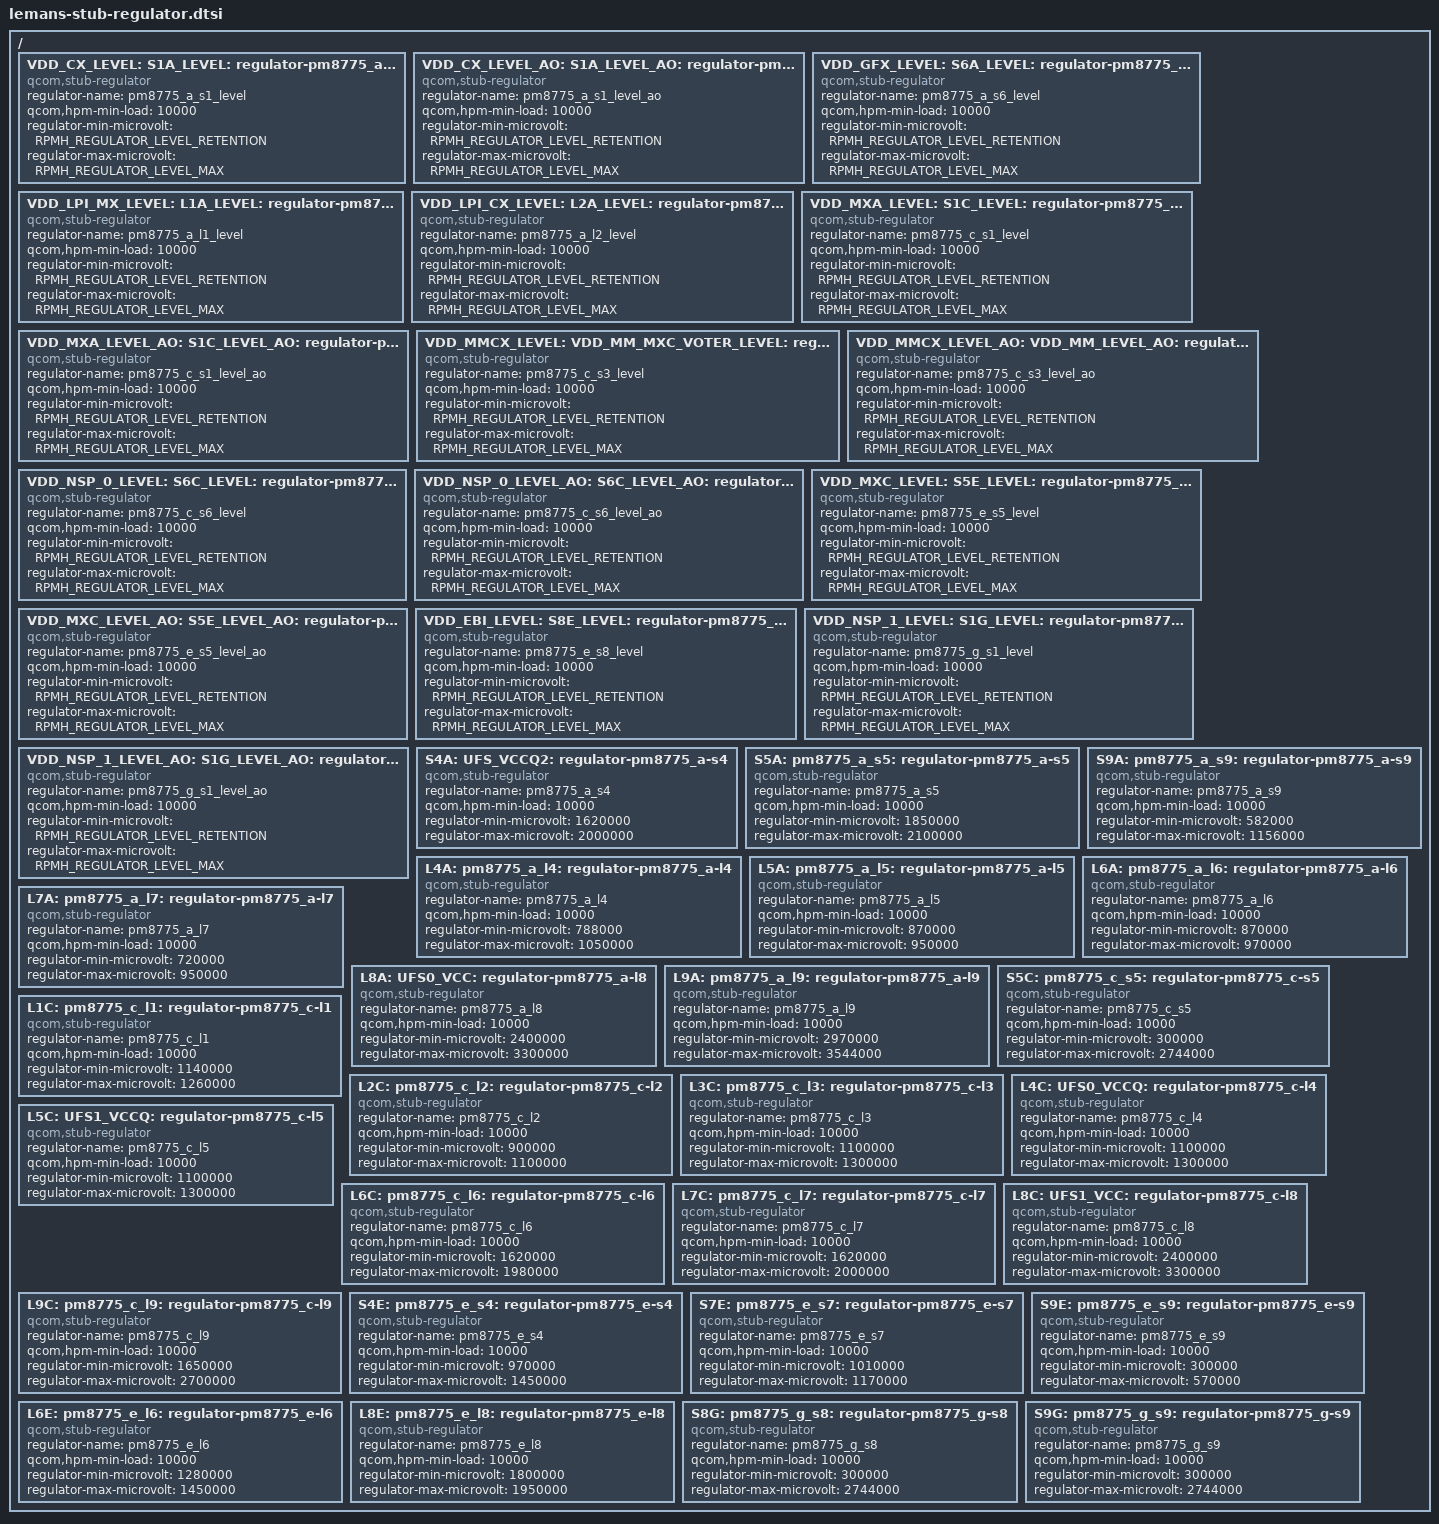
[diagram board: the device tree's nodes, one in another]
#include <dt-bindings/regulator/qcom,rpmh-regulator-levels.h>

/ {
	VDD_CX_LEVEL:
	S1A_LEVEL:
		pm8775_a_s1_level: regulator-pm8775_a-s1-level {
		compatible = "qcom,stub-regulator";
		regulator-name = "pm8775_a_s1_level";
		qcom,hpm-min-load = <10000>;
		regulator-min-microvolt =
			<RPMH_REGULATOR_LEVEL_RETENTION>;
		regulator-max-microvolt =
			<RPMH_REGULATOR_LEVEL_MAX>;
	};

	VDD_CX_LEVEL_AO:
	S1A_LEVEL_AO:
		pm8775_a_s1_level_ao: regulator-pm8775_a-s1-level-ao {
		compatible = "qcom,stub-regulator";
		regulator-name = "pm8775_a_s1_level_ao";
		qcom,hpm-min-load = <10000>;
		regulator-min-microvolt =
			<RPMH_REGULATOR_LEVEL_RETENTION>;
		regulator-max-microvolt =
			<RPMH_REGULATOR_LEVEL_MAX>;
	};

	VDD_GFX_LEVEL:
	S6A_LEVEL:
		pm8775_a_s6_level: regulator-pm8775_a-s6-level {
		compatible = "qcom,stub-regulator";
		regulator-name = "pm8775_a_s6_level";
		qcom,hpm-min-load = <10000>;
		regulator-min-microvolt =
			<RPMH_REGULATOR_LEVEL_RETENTION>;
		regulator-max-microvolt =
			<RPMH_REGULATOR_LEVEL_MAX>;
	};

	VDD_LPI_MX_LEVEL:
	L1A_LEVEL:
	pm8775_a_l1_level: regulator-pm8775_a-l1-level {
		compatible = "qcom,stub-regulator";
		regulator-name = "pm8775_a_l1_level";
		qcom,hpm-min-load = <10000>;
		regulator-min-microvolt =
			<RPMH_REGULATOR_LEVEL_RETENTION>;
		regulator-max-microvolt =
			<RPMH_REGULATOR_LEVEL_MAX>;
	};

	VDD_LPI_CX_LEVEL:
	L2A_LEVEL:
	pm8775_a_l2_level: regulator-pm8775_a-l2-level {
		compatible = "qcom,stub-regulator";
		regulator-name = "pm8775_a_l2_level";
		qcom,hpm-min-load = <10000>;
		regulator-min-microvolt =
			<RPMH_REGULATOR_LEVEL_RETENTION>;
		regulator-max-microvolt =
			<RPMH_REGULATOR_LEVEL_MAX>;
	};

	VDD_MXA_LEVEL:
	S1C_LEVEL:
	pm8775_c_s1_level: regulator-pm8775_c-s1-level {
		compatible = "qcom,stub-regulator";
		regulator-name = "pm8775_c_s1_level";
		qcom,hpm-min-load = <10000>;
		regulator-min-microvolt =
			<RPMH_REGULATOR_LEVEL_RETENTION>;
		regulator-max-microvolt =
			<RPMH_REGULATOR_LEVEL_MAX>;
	};

	VDD_MXA_LEVEL_AO:
	S1C_LEVEL_AO:
	pm8775_c_s1_level_ao: regulator-pm8775_c-s1-level-ao {
		compatible = "qcom,stub-regulator";
		regulator-name = "pm8775_c_s1_level_ao";
		qcom,hpm-min-load = <10000>;
		regulator-min-microvolt =
			<RPMH_REGULATOR_LEVEL_RETENTION>;
		regulator-max-microvolt =
			<RPMH_REGULATOR_LEVEL_MAX>;
	};

	VDD_MMCX_LEVEL:
	VDD_MM_MXC_VOTER_LEVEL:
	VDD_GX_MXC_VOTER_LEVEL:
	VDD_MM_LEVEL:
	S3C_LEVEL:
	pm8775_c_s3_level: regulator-pm8775_c-s3-level {
		compatible = "qcom,stub-regulator";
		regulator-name = "pm8775_c_s3_level";
		qcom,hpm-min-load = <10000>;
		regulator-min-microvolt =
			<RPMH_REGULATOR_LEVEL_RETENTION>;
		regulator-max-microvolt =
			<RPMH_REGULATOR_LEVEL_MAX>;
	};

	VDD_MMCX_LEVEL_AO:
	VDD_MM_LEVEL_AO:
	S3C_LEVEL_AO:
	pm8775_c_s3_level_ao: regulator-pm8775_c-s3-level-ao {
		compatible = "qcom,stub-regulator";
		regulator-name = "pm8775_c_s3_level_ao";
		qcom,hpm-min-load = <10000>;
		regulator-min-microvolt =
			<RPMH_REGULATOR_LEVEL_RETENTION>;
		regulator-max-microvolt =
			<RPMH_REGULATOR_LEVEL_MAX>;
	};

	VDD_NSP_0_LEVEL:
	S6C_LEVEL:
	pm8775_c_s6_level: regulator-pm8775_c-s6-level {
		compatible = "qcom,stub-regulator";
		regulator-name = "pm8775_c_s6_level";
		qcom,hpm-min-load = <10000>;
		regulator-min-microvolt =
			<RPMH_REGULATOR_LEVEL_RETENTION>;
		regulator-max-microvolt =
			<RPMH_REGULATOR_LEVEL_MAX>;
	};

	VDD_NSP_0_LEVEL_AO:
	S6C_LEVEL_AO:
	pm8775_c_s6_level_ao: regulator-pm8775_c-s6-level-ao {
		compatible = "qcom,stub-regulator";
		regulator-name = "pm8775_c_s6_level_ao";
		qcom,hpm-min-load = <10000>;
		regulator-min-microvolt =
			<RPMH_REGULATOR_LEVEL_RETENTION>;
		regulator-max-microvolt =
			<RPMH_REGULATOR_LEVEL_MAX>;
	};

	VDD_MXC_LEVEL:
	S5E_LEVEL:
	pm8775_e_s5_level: regulator-pm8775_e-s5-level {
		compatible = "qcom,stub-regulator";
		regulator-name = "pm8775_e_s5_level";
		qcom,hpm-min-load = <10000>;
		regulator-min-microvolt =
			<RPMH_REGULATOR_LEVEL_RETENTION>;
		regulator-max-microvolt =
			<RPMH_REGULATOR_LEVEL_MAX>;
	};

	VDD_MXC_LEVEL_AO:
	S5E_LEVEL_AO:
	pm8775_e_s5_level_ao: regulator-pm8775_e-s5-level-ao {
		compatible = "qcom,stub-regulator";
		regulator-name = "pm8775_e_s5_level_ao";
		qcom,hpm-min-load = <10000>;
		regulator-min-microvolt =
			<RPMH_REGULATOR_LEVEL_RETENTION>;
		regulator-max-microvolt =
			<RPMH_REGULATOR_LEVEL_MAX>;
	};

	VDD_EBI_LEVEL:
	S8E_LEVEL:
	pm8775_e_s8_level: regulator-pm8775_e-s8-level {
		compatible = "qcom,stub-regulator";
		regulator-name = "pm8775_e_s8_level";
		qcom,hpm-min-load = <10000>;
		regulator-min-microvolt =
			<RPMH_REGULATOR_LEVEL_RETENTION>;
		regulator-max-microvolt =
			<RPMH_REGULATOR_LEVEL_MAX>;
	};

	VDD_NSP_1_LEVEL:
	S1G_LEVEL:
	pm8775_g_s1_level: regulator-pm8775_g-s1-level {
		compatible = "qcom,stub-regulator";
		regulator-name = "pm8775_g_s1_level";
		qcom,hpm-min-load = <10000>;
		regulator-min-microvolt =
			<RPMH_REGULATOR_LEVEL_RETENTION>;
		regulator-max-microvolt =
			<RPMH_REGULATOR_LEVEL_MAX>;
	};

	VDD_NSP_1_LEVEL_AO:
	S1G_LEVEL_AO:
	pm8775_g_s1_level_ao: regulator-pm8775_g-s1-level-ao {
		compatible = "qcom,stub-regulator";
		regulator-name = "pm8775_g_s1_level_ao";
		qcom,hpm-min-load = <10000>;
		regulator-min-microvolt =
			<RPMH_REGULATOR_LEVEL_RETENTION>;
		regulator-max-microvolt =
			<RPMH_REGULATOR_LEVEL_MAX>;
	};

	S4A: UFS_VCCQ2:
	pm8775_a_s4: regulator-pm8775_a-s4 {
		compatible = "qcom,stub-regulator";
		regulator-name = "pm8775_a_s4";
		qcom,hpm-min-load = <10000>;
		regulator-min-microvolt = <1620000>;
		regulator-max-microvolt = <2000000>;
	};

	S5A:
	pm8775_a_s5: regulator-pm8775_a-s5 {
		compatible = "qcom,stub-regulator";
		regulator-name = "pm8775_a_s5";
		qcom,hpm-min-load = <10000>;
		regulator-min-microvolt = <1850000>;
		regulator-max-microvolt = <2100000>;
	};

	S9A:
	pm8775_a_s9: regulator-pm8775_a-s9 {
		compatible = "qcom,stub-regulator";
		regulator-name = "pm8775_a_s9";
		qcom,hpm-min-load = <10000>;
		regulator-min-microvolt = <582000>;
		regulator-max-microvolt = <1156000>;
	};

	L4A:
	pm8775_a_l4: regulator-pm8775_a-l4 {
		compatible = "qcom,stub-regulator";
		regulator-name = "pm8775_a_l4";
		qcom,hpm-min-load = <10000>;
		regulator-min-microvolt = <788000>;
		regulator-max-microvolt = <1050000>;
	};

	L5A:
	pm8775_a_l5: regulator-pm8775_a-l5 {
		compatible = "qcom,stub-regulator";
		regulator-name = "pm8775_a_l5";
		qcom,hpm-min-load = <10000>;
		regulator-min-microvolt = <870000>;
		regulator-max-microvolt = <950000>;
	};

	L6A:
	pm8775_a_l6: regulator-pm8775_a-l6 {
		compatible = "qcom,stub-regulator";
		regulator-name = "pm8775_a_l6";
		qcom,hpm-min-load = <10000>;
		regulator-min-microvolt = <870000>;
		regulator-max-microvolt = <970000>;
	};

	L7A:
	pm8775_a_l7: regulator-pm8775_a-l7 {
		compatible = "qcom,stub-regulator";
		regulator-name = "pm8775_a_l7";
		qcom,hpm-min-load = <10000>;
		regulator-min-microvolt = <720000>;
		regulator-max-microvolt = <950000>;
	};

	L8A: UFS0_VCC:
	pm8775_a_l8: regulator-pm8775_a-l8 {
		compatible = "qcom,stub-regulator";
		regulator-name = "pm8775_a_l8";
		qcom,hpm-min-load = <10000>;
		regulator-min-microvolt = <2400000>;
		regulator-max-microvolt = <3300000>;
	};

	L9A:
	pm8775_a_l9: regulator-pm8775_a-l9 {
		compatible = "qcom,stub-regulator";
		regulator-name = "pm8775_a_l9";
		qcom,hpm-min-load = <10000>;
		regulator-min-microvolt = <2970000>;
		regulator-max-microvolt = <3544000>;
	};

	S5C:
	pm8775_c_s5: regulator-pm8775_c-s5 {
		compatible = "qcom,stub-regulator";
		regulator-name = "pm8775_c_s5";
		qcom,hpm-min-load = <10000>;
		regulator-min-microvolt = <300000>;
		regulator-max-microvolt = <2744000>;
	};

	L1C:
	pm8775_c_l1: regulator-pm8775_c-l1 {
		compatible = "qcom,stub-regulator";
		regulator-name = "pm8775_c_l1";
		qcom,hpm-min-load = <10000>;
		regulator-min-microvolt = <1140000>;
		regulator-max-microvolt = <1260000>;
	};

	L2C:
	pm8775_c_l2: regulator-pm8775_c-l2 {
		compatible = "qcom,stub-regulator";
		regulator-name = "pm8775_c_l2";
		qcom,hpm-min-load = <10000>;
		regulator-min-microvolt = <900000>;
		regulator-max-microvolt = <1100000>;
	};

	L3C:
	pm8775_c_l3: regulator-pm8775_c-l3 {
		compatible = "qcom,stub-regulator";
		regulator-name = "pm8775_c_l3";
		qcom,hpm-min-load = <10000>;
		regulator-min-microvolt = <1100000>;
		regulator-max-microvolt = <1300000>;
	};

	L4C: UFS0_VCCQ:
	pm8775_c_l4: regulator-pm8775_c-l4 {
		compatible = "qcom,stub-regulator";
		regulator-name = "pm8775_c_l4";
		qcom,hpm-min-load = <10000>;
		regulator-min-microvolt = <1100000>;
		regulator-max-microvolt = <1300000>;
	};

	L5C: UFS1_VCCQ:
	pm8775_c_l5: regulator-pm8775_c-l5 {
		compatible = "qcom,stub-regulator";
		regulator-name = "pm8775_c_l5";
		qcom,hpm-min-load = <10000>;
		regulator-min-microvolt = <1100000>;
		regulator-max-microvolt = <1300000>;
	};

	L6C:
	pm8775_c_l6: regulator-pm8775_c-l6 {
		compatible = "qcom,stub-regulator";
		regulator-name = "pm8775_c_l6";
		qcom,hpm-min-load = <10000>;
		regulator-min-microvolt = <1620000>;
		regulator-max-microvolt = <1980000>;
	};

	L7C:
	pm8775_c_l7: regulator-pm8775_c-l7 {
		compatible = "qcom,stub-regulator";
		regulator-name = "pm8775_c_l7";
		qcom,hpm-min-load = <10000>;
		regulator-min-microvolt = <1620000>;
		regulator-max-microvolt = <2000000>;
	};

	L8C: UFS1_VCC:
	pm8775_c_l8: regulator-pm8775_c-l8 {
		compatible = "qcom,stub-regulator";
		regulator-name = "pm8775_c_l8";
		qcom,hpm-min-load = <10000>;
		regulator-min-microvolt = <2400000>;
		regulator-max-microvolt = <3300000>;
	};

	L9C:
	pm8775_c_l9: regulator-pm8775_c-l9 {
		compatible = "qcom,stub-regulator";
		regulator-name = "pm8775_c_l9";
		qcom,hpm-min-load = <10000>;
		regulator-min-microvolt = <1650000>;
		regulator-max-microvolt = <2700000>;
	};

	S4E:
	pm8775_e_s4: regulator-pm8775_e-s4 {
		compatible = "qcom,stub-regulator";
		regulator-name = "pm8775_e_s4";
		qcom,hpm-min-load = <10000>;
		regulator-min-microvolt = <970000>;
		regulator-max-microvolt = <1450000>;
	};

	S7E:
	pm8775_e_s7: regulator-pm8775_e-s7 {
		compatible = "qcom,stub-regulator";
		regulator-name = "pm8775_e_s7";
		qcom,hpm-min-load = <10000>;
		regulator-min-microvolt = <1010000>;
		regulator-max-microvolt = <1170000>;
	};

	S9E:
	pm8775_e_s9: regulator-pm8775_e-s9 {
		compatible = "qcom,stub-regulator";
		regulator-name = "pm8775_e_s9";
		qcom,hpm-min-load = <10000>;
		regulator-min-microvolt = <300000>;
		regulator-max-microvolt = <570000>;
	};

	L6E:
	pm8775_e_l6: regulator-pm8775_e-l6 {
		compatible = "qcom,stub-regulator";
		regulator-name = "pm8775_e_l6";
		qcom,hpm-min-load = <10000>;
		regulator-min-microvolt = <1280000>;
		regulator-max-microvolt = <1450000>;
	};

	L8E:
	pm8775_e_l8: regulator-pm8775_e-l8 {
		compatible = "qcom,stub-regulator";
		regulator-name = "pm8775_e_l8";
		qcom,hpm-min-load = <10000>;
		regulator-min-microvolt = <1800000>;
		regulator-max-microvolt = <1950000>;
	};

	S8G:
	pm8775_g_s8: regulator-pm8775_g-s8 {
		compatible = "qcom,stub-regulator";
		regulator-name = "pm8775_g_s8";
		qcom,hpm-min-load = <10000>;
		regulator-min-microvolt = <300000>;
		regulator-max-microvolt = <2744000>;
	};

	S9G:
	pm8775_g_s9: regulator-pm8775_g-s9 {
		compatible = "qcom,stub-regulator";
		regulator-name = "pm8775_g_s9";
		qcom,hpm-min-load = <10000>;
		regulator-min-microvolt = <300000>;
		regulator-max-microvolt = <2744000>;
	};
};
